# V32F20x_CM33 register map
File version: 1.0.3
CPU: CM33 r0p4, little endian, MPU, FPU, DSP, 3 interrupt priority bits, 8 SAU regions
Registers are 32-bit, read-write, reset 0x0 unless marked. A register's access mark holds for its fields unless they carry their own. Offsets are from the block's base; [hi:lo] are bit positions; {n}, {i} and the like mark numbered series.

## CAN0 — CAN0 Peripheral Interface
Base 0x40080000
Same registers: CAN1 0x40080800, SEC_CAN0 0x50080000, SEC_CAN1 0x50080800
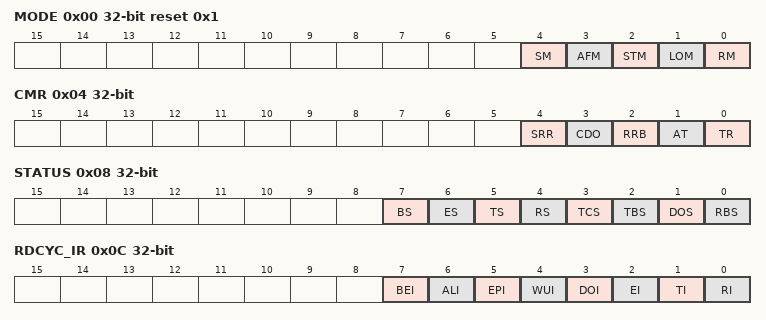
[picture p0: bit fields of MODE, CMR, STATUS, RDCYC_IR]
0x00 MODE reset 0x1 — CAN mode register
  [4] SM — Sleep Mode(Can only be written in Operating Mode)
  [3] AFM — Acceptance Filter Mode
  [2] STM — Self Test Mode
  [1] LOM — listen only mode
  [0] RM — Reset mode.
0x04 CMR wo — CAN command register
  [4] SRR — Self reception request command.
  [3] CDO — Clear data overrun command.
  [2] RRB — Release receive buffer command.
  [1] AT — Abort transmission command or don t try to resend if error
  [0] TR — Transmission Request
0x08 STATUS ro — CAN status register
  [7] BS — Bus Status
  [6] ES — Error Status
  [5] TS — Transmit Status
  [4] RS — Receive Status
  [3] TCS — Transmission Complete Status
  [2] TBS — Transmit Buffer Status
  [1] DOS — Data Overrun Status
  [0] RBS — Receive Buffer Status
0x0C RDCYC_IR ro — Interrupt register
  [7] BEI — Set when the MCAN2 detects an error on the CAN bus provided the BEIE bit IER
  [6] ALI — Set when the MCAN2 loses arbitration and becomes a receiver provided the ALIE bit IER
  [5] EPI — Set when the MCAN2 re enters error active state after being in error
  [4] WUI — Set when bus activity is detected while the CAN controller is sleeping provided the WUIE bit IER
  [3] DOI — Set on a 0 to 1 transition of the Data Overrun Status bit SR
  [2] EI — Set on every change set or clear of either the Bus Status or Error Status bits SR
  [1] TI — Set whenever the Transmit Buffer Status SR
  [0] RI — Set whenever the Receive Buffer contains one or more messages provided the RIE bit IER
0x10 IER — interrupt enable register
  [7:0] IER — Interrupt enable register 7 0 which have 8 interrupt signal
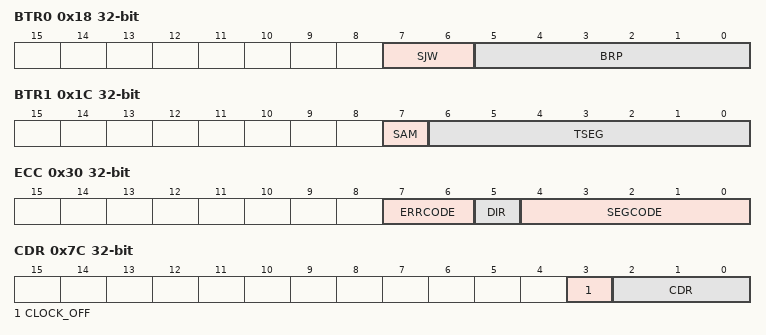
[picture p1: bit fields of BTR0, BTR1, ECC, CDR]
0x18 BTR0 — bus timing 0 register
  [7:6] SJW — The Synchronization Jump Width
  [5:0] BRP — The Baud Rate Prescaler
0x1C BTR1 — bus timing 1 register
  [7] SAM — sampling
  [6:0] TSEG — TSEG1 BTR 3 0 and TSEG2 BTR 6 4 define the length of the bit period
0x20 OCR — output control register
  [1:0] OCR — 0X: Reserved
0x2C ALC ro — arbitration lost capture register
  [7:0] ALC — output arbitration lost capture contents
0x30 ECC ro — error code capture register
  [7:6] ERRCODE — See the below table
  [5] DIR — If 1 the error occurred during reception
  [4:0] SEGCODE — See the below table
0x34 EWLR reset 0x60 — error warning limit register
  [7:0] EWLR
0x38 RXERR — receive error count register
  [7:0] RXERR — Read rx error count contents
0x3C TXERR — transmit error count register
  [7:0] TXERR — Output tx error count contents
0x40 TXBUF0 wo — Transmit frame information,Read back from 180h register
  [31:0] TXBUF0 — Transmit frame information Read back from 180h register
0x40 RXBUF0 ro (alternate view of TXBUF0) — Receive frame information register
  [31:0] RXBUF0 — Receive frame information register.
{0x40+4i} ACR{i} (alternate view of TXBUF{i}) (i=0..3) — acceptance code register0-3
  [7:0] ACR — Acceptance code register0-3
{0x40+4i} TXBUF{i} wo (i=1..12) — Transmit data information, Read back from 184h-1b0h
  [31:0] TXBUFx — Transmit data information Read back from 184h 1b0h
{0x40+4i} RXBUF{i} ro (alternate view of TXBUF{i}) (i=1..12) — Receive data information register
  [31:0] RXBUFx
{0x50+4i} AMR{i} (alternate view of TXBUF{i+4}) (i=0..3) — acceptance mask register0-3
  [7:0] AMR — Acceptance Mask register0-3
0x74 RMC ro — receive message count register
  [4:0] RMC — RX message count contents
0x78 RBSA — receive buffer start address register
  [5:0] RBSA — RX buffer start address register contents
0x7C CDR — clock divider register
  [3] CLOCK_OFF — Setting this bit allows the external CLKOUT signal to be disabled
  [2:0] CDR — clock divider register
{0x80+4i} RXFIFO{i} ro (i=0..63) — Receive FIFO register
  [31:0] RXFIFO
{0x180+4i} TXFIFO{i} wo (i=0..63) — Transmit Buffer register
  [31:0] TXFIFO
